# ET6801 register map
Vendor: ETMCU Inc.; File version: v0.0.1
CPU: CM7 r2p1, little endian, MPU, FPU, I-cache, D-cache, ITCM, DTCM, 4 interrupt priority bits
Registers are 32-bit, read-write, reset 0x0 unless marked. A register's access mark holds for its fields unless they carry their own. Offsets are from the block's base; [hi:lo] are bit positions; lines under a group give offsets from that group; {n}, {i} and the like mark numbered series.

## SRPWM0 — Provide an overview of the purpose and functionality of the peripheral: epwm_cfg
Base 0x40002000
Same registers: SRPWM{n} {0x40002000+0x1000*n} (n=1..17)
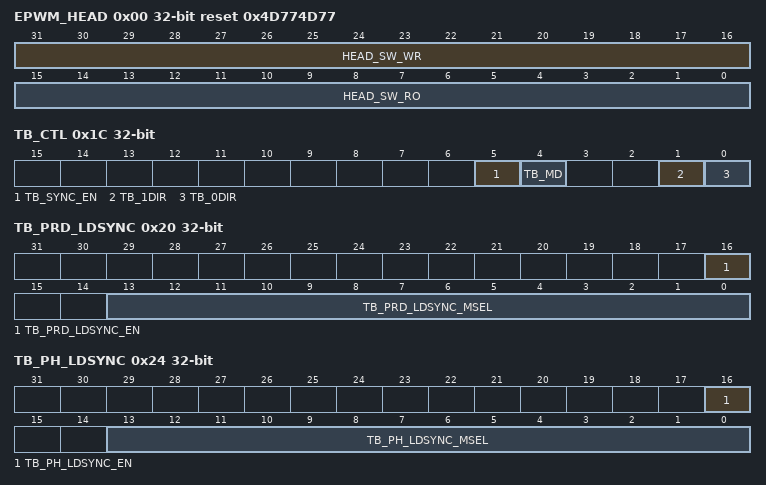
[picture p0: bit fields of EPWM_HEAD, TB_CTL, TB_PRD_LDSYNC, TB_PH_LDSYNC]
0x00 EPWM_HEAD reset 0x4D774D77
  [31:16] HEAD_SW_WR — 软件测试读写寄存器，硬件无访问
  [15:0] HEAD_SW_RO ro — 软件只读上报寄存器，硬件无访问,XXX的ASICII 码表示
0x10 TB_PRD
  [28:0] TB_PRD — timer_base计数周期配置。 高22bit为标准精度周期取值范围1~ 4194303（2^22-1），单位为SRPWM模块工作时钟周期； 低7bit为高精度周期，当高精度分辨率为156.25ps，低6比特对应0~(10-0.15625)ns，其中5ns~(10-0.15625)ns取值范围仅在上下计数模式下适用；当高精度辨率为78.125ps，低7比特对应0~(10-0.078125)ns，其中5ns~(10-0.078125)ns取值范围仅在上下计数模式下适用。 支持影子加载模式，在该模式下影子寄存器加载后才影响时基计数器的周期，影子加载同步信号选择参见CFG_TB_PRD_LDSYNC寄存器。
0x14 TB_0PHASE
  [21:0] TB_0PHASE — 时基同步信号0（从时基同步事件中选择）对应的相位配置，当时基同步信号0到来后计数器从该配置相位开始计数。支持影子加载，即配置的相位是影子加载寄存器生效后的值（影子加载寄存器生效需等相位同步加载信号生效）。
0x18 TB_1PHASE
  [21:0] TB_1PHASE — 时基同步信号1对应的相位配置，当时基同步信号1到来后计数器从该配置相位开始计数。注意！不支持影子加载，即直接使用cpu配置下来的值。
0x1C TB_CTL
  [5] TB_SYNC_EN — timer_base计数器使能（即epwm_cfg_en）是否等时基同步信号0（即sync_in0）到来后再开启使能。 注意！此配置项不止影响TIMER_BASE的计数功能，实际要影响当前通道cfg_epwm_en的生效！ 0：不用等时基同步信号，当前通道的epwm_cfg_en配置后立即生效； 1：需要等时基同步信号0预生效后，软件下发的当前通道epwm_cfg_en的值才生效，在epwm_cfg_en生效为1之前，除POSTPROTECT和SHADOW功能外的其余模块功能均不起作用。 时基同步事件包括 ，时基同步信号0的事件选择由cfg_tb_sync0_msel确定。另外，请注意前述描述中的预生效，是指事件满足立即生效，而后面描述中的时基同步信号0/1生效，是指时基同步事件满足后经过一个时钟周期的延迟后生效。
  [4] TB_MD — timer_base计数模式： 0：UP-DOWN计数； 1：UP计数。
  [1] TB_1DIR — 同步信号1计数方向，当时基同步信号1生效后计数器以该配置方向开始计数。 0：DOWN计数 1：UP计数。
  [0] TB_0DIR — 同步信号0计数方向，当时基同步信号0生效后计数器以该配置方向开始计数。 0：DOWN计数 1：UP计数。
0x20 TB_PRD_LDSYNC
  [16] TB_PRD_LDSYNC_EN — timer_base周期同步加载使能配置。 0：不同步加载，配置后立即生效； 1：同步加载，配置后等周期同步加载信号（来自于对同步加载事件集合1的选择）到来后生效。
  [13:0] TB_PRD_LDSYNC_MSEL — timer_base周期同步加载同步信号选择，从同步加载事件集合1中选择，采用Mask_OR的方式。
0x24 TB_PH_LDSYNC
  [16] TB_PH_LDSYNC_EN — timer_base相位同步加载使能配置。 0：不同步加载，配置后cfg_tb_0phase立即生效； 1：同步加载，配置后等相位同步加载信号（来自于对同步加载事件集合1的选择）到来后cfg_tb_0phase才生效。 注意： 这里的同步信号到来后生效是指同步信号到来后此配置值可用，并不是已加载到时基计数器中，真正加载到时基计数器中改变其相位，需等时基同步信号0生效； cfg_tb_1phase不受此配置影响，cfg_tb_1phase只支持立即生效模式；
  [13:0] TB_PH_LDSYNC_MSEL — timer_base相位同步加载同步信号选择，从同步加载事件集合1中选择，采用Mask_OR的方式。
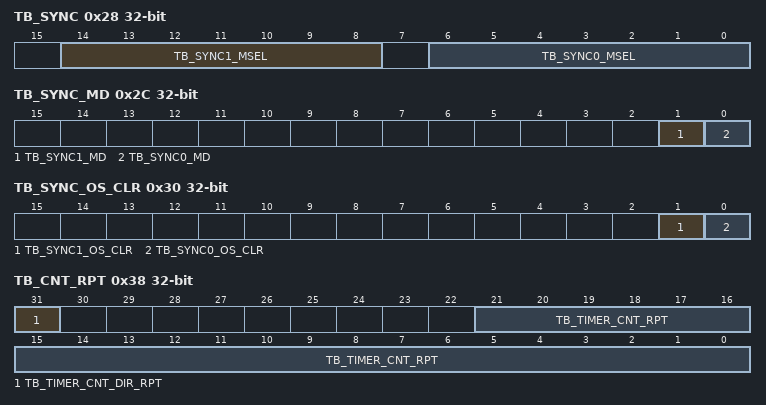
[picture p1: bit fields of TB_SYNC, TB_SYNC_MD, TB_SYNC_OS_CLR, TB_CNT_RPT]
0x28 TB_SYNC
  [14:8] TB_SYNC1_MSEL — timer_base 同步信号1选择，从时基计数器同步事件集合中选择，采用Mask_OR方式
  [6:0] TB_SYNC0_MSEL — timer_base 同步信号0选择，从时基计数器同步事件集合中选择，采用Mask_OR方式。
0x2C TB_SYNC_MD
  [1] TB_SYNC1_MD — timer_base 同步信号1的工作模式： 'b0：连续响应模式，只要有同步信号1出现，均会进行时基同步动作（将时基计数器计数值置为cfg_tb_1phase的活跃值）； 'b1：ONESHOT模式，出现一次同步信号1，并进行相应的时基同步动作后，不再响应后继的同步信号1，直至寄存器cfg_tb_sync1_os_clr写1产生清零脉冲再响应下一次同步信号1。
  [0] TB_SYNC0_MD — timer_base 同步信号0的工作模式： 'b0：连续响应模式，只要有同步信号0出现，均会进行时基同步动作（将时基计数器计数值置为cfg_tb_0phase的活跃值）； 'b1：ONESHOT模式，出现一次同步信号0，并进行相应的时基同步动作后，不再响应后继的同步信号0，直至寄存器cfg_tb_sync0_os_clr写1产生清零脉冲再响应下一次同步信号0。
0x30 TB_SYNC_OS_CLR
  [1] TB_SYNC1_OS_CLR — timer_base 同步信号1的ONESHOT锁存清除，写1产生脉冲。在ONESHOT工作模式下的同步信号1响应一次后忽略后继同步信号1，当前寄存器写1产生脉冲后，方可继续再响应下一次同步信号1。
  [0] TB_SYNC0_OS_CLR — timer_base 同步信号0的ONESHOT锁存清除，写1产生脉冲。在ONESHOT工作模式下的同步信号0响应一次后忽略后继同步信号0，当前寄存器写1产生脉冲后，方可继续再响应下一次同步信号0。
0x34 TB_RPT
  [0] TB_TIMER_OVER_RPT — timer_base 计数器溢出上报寄存器，当timer计数异常等于16'hFFFF时上报告警。软件写1清零。
0x38 TB_CNT_RPT ro
  [31] TB_TIMER_CNT_DIR_RPT — timer_base 计数器的计数方向实时上报
  [21:0] TB_TIMER_CNT_RPT — timer_base 计数器的计数值实时上报
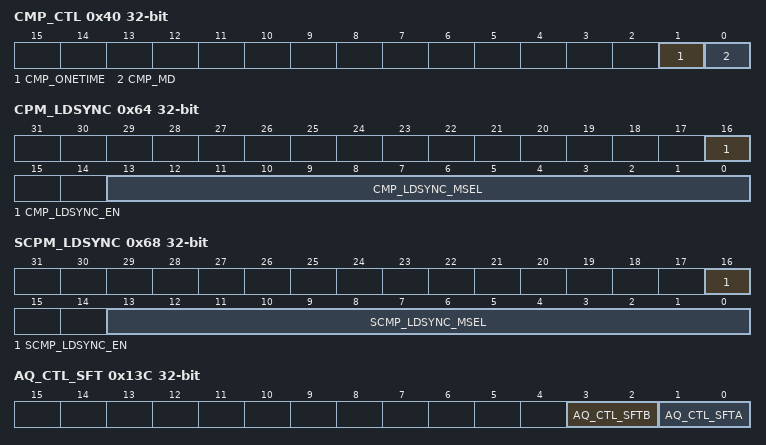
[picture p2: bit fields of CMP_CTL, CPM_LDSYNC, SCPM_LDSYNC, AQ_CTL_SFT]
0x40 CMP_CTL
  [1] CMP_ONETIME — 在一个UP或DOWN的方向上只产生1次比较事件或多次事件配置。 0：产生多次事件； 1：只产生1次事件。
  [0] CMP_MD — 0：主比较器向上或向下方向产生相等事件； 1：主比较器向上方向产生大于等于事件，向下方向产生小于等于事件。
0x44 CMP_CMPA
  [27:0] CMP_CMPA — 主比较事件A的比较位置配置。 高22bit为标准精度比较值，可用于产生比较事件，低6bit为高精度，用于高精度发波信号的占空比微调，当高精度分辨率为156.25ps，低5比特有效，对应0~(5-0.15625)ns；当高精度辨率为78.125ps，低6比特有效，对应0~(5-0.078125)ns。
0x48 CMP_CMPB
  [27:0] CMP_CMPB — 主比较事件B的比较位置配置。 高22bit为标准精度比较值，可用于产生比较事件，低6bit为高精度，用于高精度发波信号的占空比微调，当高精度分辨率为156.25ps，低5比特有效，对应0~(5-0.15625)ns；当高精度辨率为78.125ps，低6比特有效，对应0~(5-0.078125)ns。
0x4C CMP_CMPC
  [27:0] CMP_CMPC — 主比较事件C的比较位置配置。 高22bit为标准精度比较值，可用于产生比较事件，低6bit为高精度，用于高精度发波信号的占空比微调，当高精度分辨率为156.25ps，低5比特有效，对应0~(5-0.15625)ns；当高精度辨率为78.125ps，低6比特有效，对应0~(5-0.078125)ns。
0x50 CMP_CMPD
  [27:0] CMP_CMPD — 主比较事件D的比较位置配置。 高22bit为标准精度比较值，可用于产生比较事件，低6bit为高精度，用于高精度发波信号的占空比微调，当高精度分辨率为156.25ps，低5比特有效，对应0~(5-0.15625)ns；当高精度辨率为78.125ps，低6比特有效，对应0~(5-0.078125)ns。
0x54 CMP_SCMPA
  [21:0] CMP_SCMPA — 从比较事件A的比较位置配置。
0x58 CMP_SCMPB
  [21:0] CMP_SCMPB — 从比较事件B的比较位置配置。
0x5C CMP_SCMPC
  [21:0] CMP_SCMPC — 从比较事件C的比较位置配置。
0x60 CMP_SCMPD
  [21:0] CMP_SCMPD — 从比较事件D的比较位置配置。
0x64 CPM_LDSYNC
  [16] CMP_LDSYNC_EN — 主比较事件同步加载使能配置。 0：不同步加载，配置后立即生效； 1：同步加载，配置后等同步信号到来后生效。
  [13:0] CMP_LDSYNC_MSEL — 主比较事件同步加载同步信号选择，从同步加载事件集合1中选择，采用Mask_OR方式。
0x68 SCPM_LDSYNC
  [16] SCMP_LDSYNC_EN — 从比较事件同步加载使能配置。 0：不同步加载，配置后立即生效； 1：同步加载，配置后等同步信号到来后生效。
  [13:0] SCMP_LDSYNC_MSEL — 从比较事件同步加载同步信号选择，从同步加载事件集合1中选择，采用Mask_OR方式。
{0x80+4i} AQ_CTLA[{i}] (i=0..21) — AQ_CTLA%S
  [1:0] AQ_CTLA — 产生epwma信号的动作矩阵配置，对于每一个可能触发AQ动作的事件均有一个地址对应其动作配置。共有22个动作矩阵事件可用来触发动作矩阵动作，参见《ET6001 SPWM模块逻辑需求规格书》中关于动作矩阵事件集合的定义。 00：不动作； 01：输出ePWMA和/或ePWMB 置0； 10：输出ePWMA和/或ePWMB 置1； 11：输出ePWMA和/或ePWMB 取反；
{0xE0+4i} AQ_CTLB[{i}] (i=0..21) — AQ_CTLB%S
  [1:0] AQ_CTLB — 产生epwmb信号的动作矩阵配置。对于每一个可能触发AQ动作的事件均有一个地址对应其动作配置。共有22个动作矩阵事件可用来触发动作矩阵动作，参见《ET6002 SRPWM模块逻辑需求规格书》中关于动作矩阵事件集合的定义。 00：不动作； 01：输出ePWMA和/或ePWMB 置0； 10：输出ePWMA和/或ePWMB 置1； 11：输出ePWMA和/或ePWMB 取反；
0x13C AQ_CTL_SFT
  [3:2] AQ_CTL_SFTB — 软件产生epwmb信号的动作矩阵配置。配1产生软件强制动作，优先级高于其他22个动作矩阵事件。
  [1:0] AQ_CTL_SFTA — 软件产生epwma信号的动作矩阵配置。配1产生软件强制动作，优先级高于其他22个动作矩阵事件。
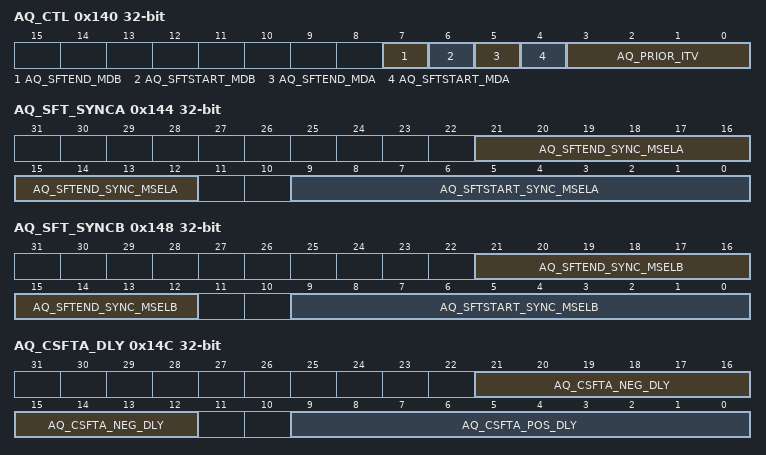
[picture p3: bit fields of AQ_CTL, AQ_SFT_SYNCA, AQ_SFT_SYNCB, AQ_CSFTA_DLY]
0x140 AQ_CTL
  [7] AQ_SFTEND_MDB — epwmb信号软件强制动作结束模式配置 0：不同步；cfg_aq_ctl_sftb写0后，软件强制动作立即失效。 1：同步；cfg_aq_ctl_sftb写0后，还需等待结束同步信号生效，软件强制动作才失效。
  [6] AQ_SFTSTART_MDB — epwmb信号软件强制动作起始模式配置 0：不同步；cfg_aq_ctl_sftb写1后，软件强制动作立即生效。 1：同步；cfg_aq_ctl_sftb写1后，还需等待开始同步信号生效，软件强制动作才生效。
  [5] AQ_SFTEND_MDA — epwma信号软件强制动作结束模式配置 0：不同步；cfg_aq_ctl_sfta写0后，软件强制动作立即失效。 1：同步；cfg_aq_ctl_sfta写0后，还需等待结束同步信号生效，软件强制动作才失效。
  [4] AQ_SFTSTART_MDA — epwma信号软件强制动作起始模式配置 0：不同步；cfg_aq_ctl_sfta写1后，软件强制动作立即生效。 1：同步；cfg_aq_ctl_sfta写1后，还需等待开始同步信号生效，软件强制动作才生效。
  [3:0] AQ_PRIOR_ITV — 动作矩阵优先级间隔长度配置。
0x144 AQ_SFT_SYNCA
  [21:12] AQ_SFTEND_SYNC_MSELA — epwma信号软件强制动作结束同步信号选择。从AQ同步事件集合中选择。采用Mask_OR方式
  [9:0] AQ_SFTSTART_SYNC_MSELA — epwma信号软件强制动作起始同步信号选择。从AQ同步事件集合中选择。采用Mask_OR方式
0x148 AQ_SFT_SYNCB
  [21:12] AQ_SFTEND_SYNC_MSELB — epwmb信号软件强制动作结束同步信号选择。从AQ同步事件集合中选择。采用Mask_OR方式
  [9:0] AQ_SFTSTART_SYNC_MSELB — epwmb信号软件强制动作起始同步信号选择。从AQ同步事件集合中选择。采用Mask_OR方式
0x14C AQ_CSFTA_DLY
  [21:12] AQ_CSFTA_NEG_DLY — epwma信号软件触发持续动作的下降沿后推延迟配置。
  [9:0] AQ_CSFTA_POS_DLY — epwma信号软件触发持续动作的上升沿后推延迟配置。
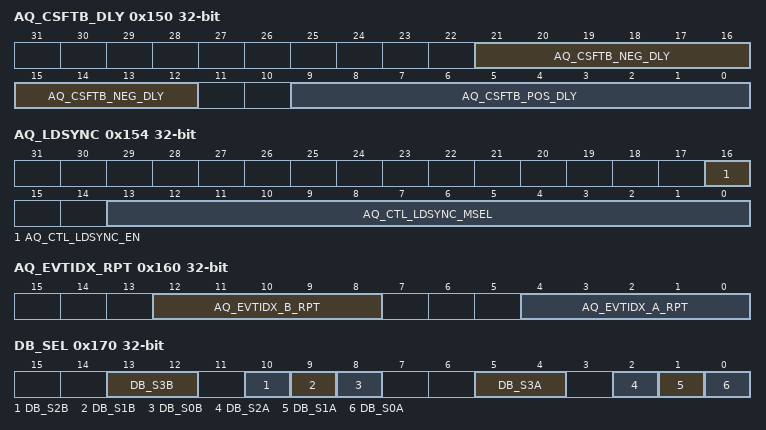
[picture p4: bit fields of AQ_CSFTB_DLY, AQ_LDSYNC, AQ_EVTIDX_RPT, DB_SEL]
0x150 AQ_CSFTB_DLY
  [21:12] AQ_CSFTB_NEG_DLY — epwmb信号软件触发持续动作的下降沿后推延迟配置。
  [9:0] AQ_CSFTB_POS_DLY — epwmb信号软件触发持续动作的上升沿后推延迟配置。
0x154 AQ_LDSYNC
  [16] AQ_CTL_LDSYNC_EN — AQ动作矩阵同步加载使能配置。 0：不同步加载，配置后立即生效； 1：同步加载，配置后等同步信号到来后生效。
  [13:0] AQ_CTL_LDSYNC_MSEL — AQ动作矩阵同步加载同步信号选择，从同步加载事件集合2中选择，采用Mask_OR方式
0x160 AQ_EVTIDX_RPT ro
  [12:8] AQ_EVTIDX_B_RPT — 产生动作矩阵B的事件优先级排序后的索引；具体索引对应事件： ；用于维测。
  [4:0] AQ_EVTIDX_A_RPT — 产生动作矩阵A的事件优先级排序后的索引；具体索引对应事件： ；用于维测。
0x170 DB_SEL
  [13:12] DB_S3B — epwmb信号死区第3个MUX选择 0：选择不做任何延迟的，旁路输出，即选择DB模块的输入作为输出； 1：选择经过上升沿或下降沿延迟之后的，即第2个MUX的输出。 2：选择将第2个MUX的输出取反后输出。
  [10] DB_S2B — epwmb信号死区第2个MUX选择 0：选择不做下降沿延迟的，即选择第1个MUX的输入作为输出； 1：选择下降沿延迟之后的。
  [9] DB_S1B — epwmb信号死区第1个MUX，选择送往下降沿延迟逻辑的信号 0：选择不做上升沿延迟，即选择第0个MUX的输入作为输出； 1：选择上升沿延迟之后的。
  [8] DB_S0B — epwmb信号死区第0个MUX，选择送往上升沿延迟逻辑的信号。 0：选择epwmb信号； 1：选择epwma信号。
  [5:4] DB_S3A — epwma信号死区第3个MUX选择 0：选择不做任何延迟的，旁路输出，即选择DB模块的输入作为输出； 1：选择经过上升沿或下降沿延迟之后的，即第2个MUX的输出。 2：选择将第2个MUX的输出取反后输出。
  [2] DB_S2A — epwma信号死区第2个MUX选择 0：选择不做下降沿延迟的，即选择第1个MUX的输入作为输出； 1：选择下降沿延迟之后的。
  [1] DB_S1A — epwma信号死区第1个MUX选择，选择送往下降沿延迟逻辑的信号 0：选择不做上升沿延迟，即选择第0个MUX的输入作为输出； 1：选择上升沿延迟之后的。
  [0] DB_S0A — epwma信号死区第0个MUX选择 0：选择epwma信号； 1：选择epwmb信号。
0x174 DB_APOS_DLY
  [19:0] DB_APOS_DLY — epwma 上升沿延迟配置。高14bit为低精度，用于DB模块调整发波信号上升沿，低6bit为高精度，用于微调高精度发波信号的上升沿。
0x178 DB_ANEG_DLY
  [19:0] DB_ANEG_DLY — epwma 下降沿延迟配置。高14bit为低精度，用于DB模块调整发波信号下降沿，低6bit为高精度，用于微调高精度发波信号的下降沿。
0x17C DB_BPOS_DLY
  [19:0] DB_BPOS_DLY — epwmb 上升沿延迟配置。高14bit为低精度，用于DB模块调整发波信号上升沿，低6bit为高精度，用于微调高精度发波信号的上升沿。
0x180 DB_BNEG_DLY
  [19:0] DB_BNEG_DLY — epwmb 下降沿延迟配置。高14bit为低精度，用于DB模块调整发波信号下降沿，低6bit为高精度，用于微调高精度发波信号的下降沿。
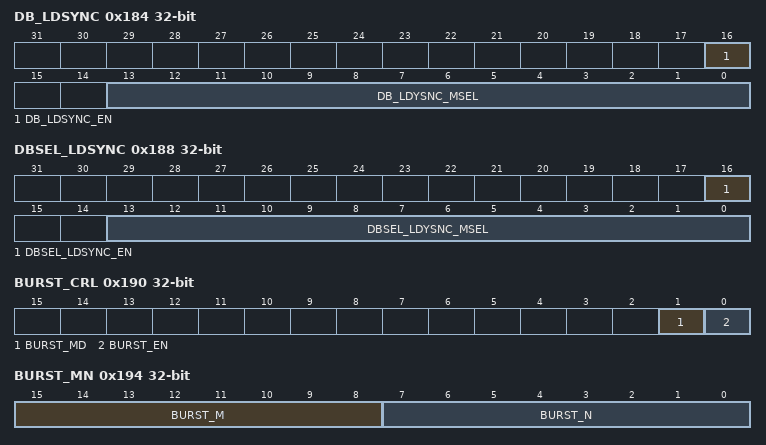
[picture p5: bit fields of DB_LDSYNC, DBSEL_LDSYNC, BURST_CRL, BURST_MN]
0x184 DB_LDSYNC
  [16] DB_LDSYNC_EN — 死区配置同步加载使能配置。 0：不同步加载，配置后立即生效； 1：同步加载，配置后等同步信号到来后生效。
  [13:0] DB_LDYSNC_MSEL — 死区同步加载同步信号选择，从同步加载事件集合2中选择，采用Mask_OR的方式。
0x188 DBSEL_LDSYNC
  [16] DBSEL_LDSYNC_EN — CFG_DB_SEL寄存器的同步加载使能。 0：不同步加载，配置后立即生效； 1：同步加载，配置后等同步信号到来后生效。
  [13:0] DBSEL_LDYSNC_MSEL — CFG_DB_SEL寄存器的同步加载同步信号选择，从同步加载事件集合2中选择，采用Mask_OR的方式。
0x190 BURST_CRL
  [1] BURST_MD — Burst模式选择配置。 0：Burst模式时先不发波； 1：Burst模式时先发波。
  [0] BURST_EN — Burst模块使能配置。 0：不使能； 1：使能。
0x194 BURST_MN
  [15:8] BURST_M — Burst模式M个周期配置。BURST模式使能后，在M个周期中有N个周期发波，M-N个周期不发波。
  [7:0] BURST_N — Burst模式n个周期发波配置。
0x198 BURST_SYNC_SEL
  [5:0] BURST_SYNC_MSEL — 开始发Burst波的同步信号选择，从BURST同步事件集合中选择，采用Mask_OR的方式。
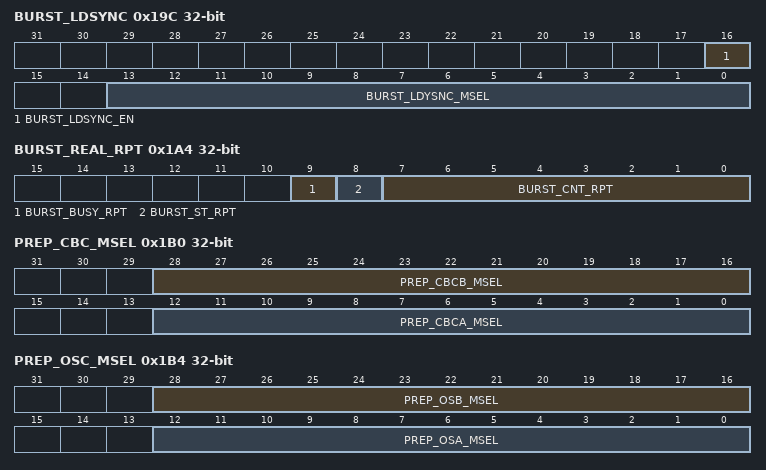
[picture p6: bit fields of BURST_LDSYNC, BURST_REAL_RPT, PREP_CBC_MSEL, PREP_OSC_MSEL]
0x19C BURST_LDSYNC
  [16] BURST_LDSYNC_EN — Burst模式m和n配置同步加载使能配置。 0：不同步加载，配置后立即生效； 1：同步加载，配置后等同步信号到来后生效。
  [13:0] BURST_LDYSNC_MSEL — Burst模式m和n配置同步信号选择，从同步加载事件集合1选择，采用Mask_OR的方式。
0x1A4 BURST_REAL_RPT ro
  [9] BURST_BUSY_RPT — BURST busy状态上报，为1表示当前还工作在BURST状态中；为0表示退出了BURST工作状态。
  [8] BURST_ST_RPT — BURST 状态上报；0: 表示BUSRT处于M/N的N个发波区间； 1: 表示BUSRT处于m/n 的M-N个不发波区间。
  [7:0] BURST_CNT_RPT — BURST 1~n次计数器的计数上报；用于维测
0x1B0 PREP_CBC_MSEL
  [28:16] PREP_CBCB_MSEL — 对epwmb信号进行CBC异常保护的mask_or选择信号，对于同步保护动作，从以下事件选择：
  [12:0] PREP_CBCA_MSEL — 对epwma信号进行CBC异常保护的mask_or选择信号，对于同步保护动作，从以下事件选择：
0x1B4 PREP_OSC_MSEL
  [28:16] PREP_OSB_MSEL — 对epwmb信号进行one shot异常保护的mask_or选择信号，对于同步保护动作，从以下事件选择：
  [12:0] PREP_OSA_MSEL — 对epwma信号进行one shot异常保护的mask_or选择信号，对于同步保护动作，从以下事件选择：
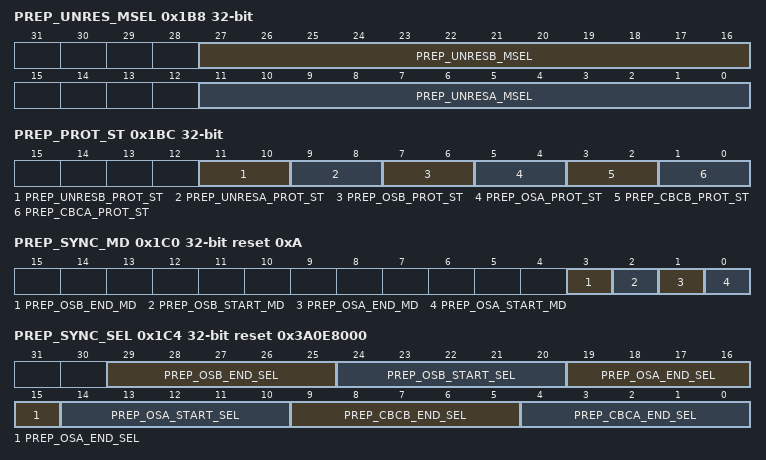
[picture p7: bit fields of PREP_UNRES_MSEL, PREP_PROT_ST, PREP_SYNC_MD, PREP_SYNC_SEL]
0x1B8 PREP_UNRES_MSEL
  [27:16] PREP_UNRESB_MSEL — 对epwma信号进行无约束异常保护的mask选择信号，对于同步保护动作，从以下事件选择：
  [11:0] PREP_UNRESA_MSEL — 对epwmb信号进行无约束异常保护的mask选择信号，对于同步保护动作，从以下事件选择：
0x1BC PREP_PROT_ST
  [11:10] PREP_UNRESB_PROT_ST — 对epwmb信号进行自由保护时保护状态配置。 00：高阻； 01：输出0； 10：输出1； 11：取反。
  [9:8] PREP_UNRESA_PROT_ST — 对epwma信号进行自由保护时保护状态配置。 00：高阻； 01：输出0； 10：输出1； 11：取反。
  [7:6] PREP_OSB_PROT_ST — 对epwmb信号进行one shot保护时保护状态配置。 00：高阻； 01：输出0； 10：输出1； 11：取反。
  [5:4] PREP_OSA_PROT_ST — 对epwma信号进行one shot保护时保护状态配置。 00：高阻； 01：输出0； 10：输出1； 11：取反。
  [3:2] PREP_CBCB_PROT_ST — 对epwmb信号进行CBC保护时保护状态配置。 00：高阻； 01：输出0； 10：输出1； 11：取反。
  [1:0] PREP_CBCA_PROT_ST — 对epwma信号进行CBC保护时保护状态配置。 00：高阻； 01：输出0； 10：输出1； 11：取反。
0x1C0 PREP_SYNC_MD reset 0xA
  [3] PREP_OSB_END_MD — 对epwmb信号进行one shot保护时是否需要同步结束配置，默认需要同步结束。 0：不需要同步； 1：需要同步。
  [2] PREP_OSB_START_MD — 对epwmb信号进行one shot保护时是否需要同步开始配置。 0：不需要同步； 1：需要同步。
  [1] PREP_OSA_END_MD — 对epwma信号进行one shot保护时是否需要同步结束配置，默认需要同步结束。 0：不需要同步； 1：需要同步。
  [0] PREP_OSA_START_MD — 对epwma信号进行one shot保护时是否需要同步开始配置。 0：不需要同步； 1：需要同步。
0x1C4 PREP_SYNC_SEL reset 0x3A0E8000
  [29:25] PREP_OSB_END_SEL — epwmb信号oneshot保护结束同步信号选择，从所有事件集合中选择，默认以软件强制事件结束。
  [24:20] PREP_OSB_START_SEL — epwmb信号oneshot保护起始同步信号选择，从所有事件集合中选择。
  [19:15] PREP_OSA_END_SEL — epwma信号oneshot保护结束同步信号选择，从所有事件集合中选择，默认以软件强制事件结束。
  [14:10] PREP_OSA_START_SEL — epwma信号oneshot保护起始同步信号选择，从所有事件集合中选择。
  [9:5] PREP_CBCB_END_SEL — epwmb信号CBC保护结束同步信号选择，从所有事件集合中选择。
  [4:0] PREP_CBCA_END_SEL — epwma信号CBC保护结束同步信号选择，从所有事件集合中选择。
0x1C8 PREP_UNRES_MIN_TIME
  [15:0] PREP_UNRES_MIN_TIME — 无约束保护最小脉宽时间配置。单位为PWM模块工作时钟周期数。
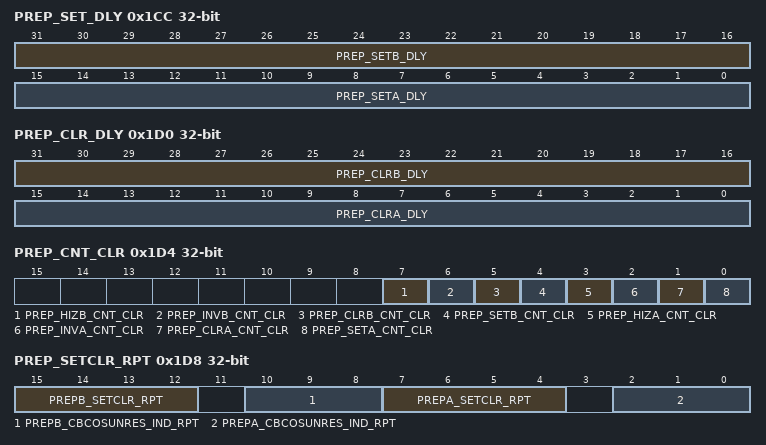
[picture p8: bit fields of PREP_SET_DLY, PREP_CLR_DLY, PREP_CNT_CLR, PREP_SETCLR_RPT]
0x1CC PREP_SET_DLY
  [31:16] PREP_SETB_DLY — epwmb置1保护动作延迟配置，取值范围0~65535，单位为SPWM模块工作时钟周期。该配置值将相应保护动作实际起始时间延后（保护动作结束时间不受影响），当置'd0值时，保护动作不做延迟，配置值为N时，保护动作起始时间延后N个时钟周期。保护动作结束时刻不受此配置值影响。 准静态配置寄存器，在pwm_en为低时才能改变配置
  [15:0] PREP_SETA_DLY — epwma置1保护动作延迟配置，取值范围0~65535，单位为SPWM模块工作时钟周期。该配置值将相应保护动作实际起始时间延后（保护动作结束时间不受影响），当置'd0值时，保护动作不做延迟，配置值为N时，保护动作起始时间延后N个时钟周期。保护动作结束时刻不受此配置值影响。 准静态配置寄存器，在pwm_en为低时才能改变配置。
0x1D0 PREP_CLR_DLY
  [31:16] PREP_CLRB_DLY — epwmb清零保护动作延迟配置，取值范围0~65535，单位为SPWM模块工作时钟周期。该配置值将相应保护动作实际起始时间延后（保护动作结束时间不受影响），当置'd0值时，保护动作不做延迟，配置值为N时，保护动作起始时间延后N个时钟周期。保护动作结束时刻不受此配置值影响。 准静态配置寄存器，在pwm_en为低时才能改变配置
  [15:0] PREP_CLRA_DLY — epwma清零保护动作延迟配置，取值范围0~65535，单位为SPWM模块工作时钟周期。该配置值将相应保护动作实际起始时间延后（保护动作结束时间不受影响），当置'd0值时，保护动作不做延迟，配置值为N时，保护动作起始时间延后N个时钟周期。保护动作结束时刻不受此配置值影响。 准静态配置寄存器，在pwm_en为低时才能改变配置。
0x1D4 PREP_CNT_CLR
  [7] PREP_HIZB_CNT_CLR — epwmb 高阻时间计数器清零，写1清零；
  [6] PREP_INVB_CNT_CLR — epwmb 取反时间计数器清零，写1清零；
  [5] PREP_CLRB_CNT_CLR — epwmb 清零时间计数器清零，写1清零；
  [4] PREP_SETB_CNT_CLR — epwmb 置1时间计数器清零，写1清零；
  [3] PREP_HIZA_CNT_CLR — epwma 高阻时间计数器清零，写1清零；
  [2] PREP_INVA_CNT_CLR — epwma 取反时间计数器清零，写1清零；
  [1] PREP_CLRA_CNT_CLR — epwma 清零时间计数器清零，写1清零；
  [0] PREP_SETA_CNT_CLR — epwma 置1时间计数器清零，写1清零；
0x1D8 PREP_SETCLR_RPT ro
  [15:12] PREPB_SETCLR_RPT — 控制epwmb信号置1，清零，取反和输出高阻的指示信号上报。 bit0：输出高阻指示； bit1：输出取反指示； bit2：输出清零指示； bit3：输出置1指示。
  [10:8] PREPB_CBCOSUNRES_IND_RPT — 控制epwmb信号oneshot指示，cbc指示以及无约束保护指示上报 bit0：无约束保护指示；bit1：oneshot保护指示；bit2：CBC保护指示。
  [7:4] PREPA_SETCLR_RPT — 控制epwma信号置1，清零，取反和输出高阻的指示信号上报。 bit0：输出高阻指示； bit1：输出取反指示； bit2：输出清零指示； bit3：输出置1指示。
  [2:0] PREPA_CBCOSUNRES_IND_RPT — 控制epwma信号oneshot指示，cbc指示以及自由保护指示上报 bit0：无约束保护指示；bit1：oneshot保护指示；bit2：CBC保护指示。
0x1DC PREPA_SET_CNT_RPT ro
  [21:0] PREPA_SET_CNT_RPT — epwma被异常置1的时间长度计数上报。
0x1E0 PREPB_SET_CNT_RPT ro
  [21:0] PREPB_SET_CNT_RPT — epwmb被异常置1的时间长度计数上报。
0x1E4 PREPA_CLR_CNT_RPT ro
  [21:0] PREPA_CLR_CNT_RPT — epwma被异常清零的时间长度计数上报。
0x1E8 PREPB_CLR_CNT_RPT ro
  [21:0] PREPB_CLR_CNT_RPT — epwmb被异常清零的时间长度计数上报。
0x1EC PREPA_INV_CNT_RPT ro
  [21:0] PREPA_INV_CNT_RPT — epwma被异常取反的时间长度计数上报。
0x1F0 PREPB_INV_CNT_RPT ro
  [21:0] PREPB_INV_CNT_RPT — epwmb被异常取反的时间长度计数上报。
0x1F4 PREPA_HIZ_CNT_RPT ro
  [21:0] PREPA_HIZ_CNT_RPT — epwma被异常置高阻的时间长度计数上报。
0x1F8 PREPB_HIZ_CNT_RPT ro
  [21:0] PREPB_HIZ_CNT_RPT — epwmb被异常置高阻的时间长度计数上报。
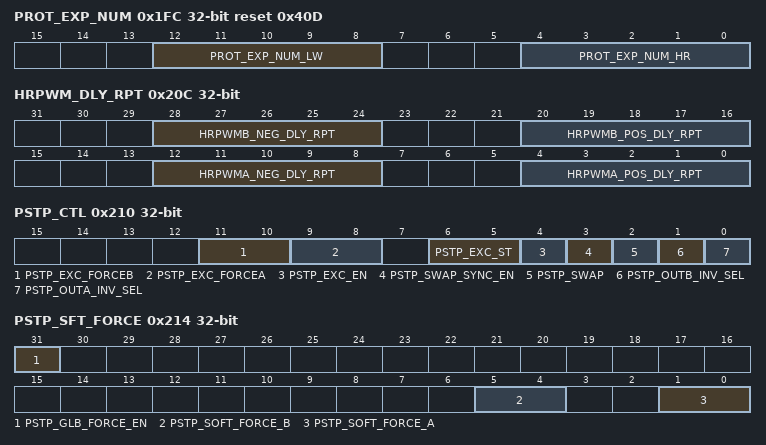
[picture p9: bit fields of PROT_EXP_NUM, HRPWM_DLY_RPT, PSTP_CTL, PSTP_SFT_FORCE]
0x1FC PROT_EXP_NUM reset 0x40D
  [12:8] PROT_EXP_NUM_LW — 未启用高精度时，快速保护动作脉冲扩展时钟周期，当扩展前脉冲宽度小于cfg_prot_exp_num_lw+1，则扩展后脉冲宽度变为cfg_prot_exp_num_lw+1，如果扩展前脉冲宽度大于等于cfg_prot_exp_num_lw+1，则扩展后脉冲宽度不变： 'd0：不做脉冲扩展； 'd1：扩展一个时钟周期； ... 准静态配置寄存器，在pwm_en为低时才能改变配置
  [4:0] PROT_EXP_NUM_HR — 高精度生效时，快速保护动作脉冲扩展时钟周期，当扩展前脉冲宽度小于cfg_prot_exp_num_hr +1，则扩展后脉冲宽度变为cfg_prot_exp_num_hr +1，如果扩展前脉冲宽度大于等于cfg_prot_exp_num_hr +1，则扩展后脉冲宽度不变： 'd0：不做脉冲扩展； 'd1：扩展一个时钟周期； ... 准静态配置寄存器，在pwm_en为低时才能改变配置。
0x200 HRPWM_BPS
  [1] HRPWM_BPS — 高精度PWM旁路使能。 0：不旁路； 1：旁路。
0x20C HRPWM_DLY_RPT ro
  [28:24] HRPWMB_NEG_DLY_RPT — ePWMB的下降沿的高精度延迟值上报。
  [20:16] HRPWMB_POS_DLY_RPT — ePWMB的上升沿的高精度延迟值上报。
  [12:8] HRPWMA_NEG_DLY_RPT — ePWMA的下降沿的高精度延迟值上报。
  [4:0] HRPWMA_POS_DLY_RPT — ePWMA的上升沿的高精度延迟值上报。
0x210 PSTP_CTL
  [11:10] PSTP_EXC_FORCEB — epwma和epwmb互斥后b输出状态配置。 00：不动作； 01：输出1； 10：输出0； 11：输出高阻。
  [9:8] PSTP_EXC_FORCEA — epwma和epwmb互斥后a输出状态配置。 00：不动作； 01：输出1； 10：输出0； 11：输出高阻。
  [6:5] PSTP_EXC_ST — epwma和epwmb互斥状态配置。 00：a和b同时为低产生互斥； 01：a为低，b为高产生互斥； 10：a为高，b为低产生互斥； 11：a和b同时为高产生互斥。
  [4] PSTP_EXC_EN — epwm输出互斥检测使能 0：不使能； 1：使能。
  [3] PSTP_SWAP_SYNC_EN — epwma和epwmb输出交换是否需要等到同步信号再交换选择。 0：不需要同步； 1：需要同步。
  [2] PSTP_SWAP — epwma和epwmb输出信号是否需要交换选择； 0：不交换； 1：交换。
  [1] PSTP_OUTB_INV_SEL — epwmb输出是否取反选择 0：不取反 1：取反
  [0] PSTP_OUTA_INV_SEL — epwma输出是否取反选择 0：不取反 1：取反
0x214 PSTP_SFT_FORCE
  [31] PSTP_GLB_FORCE_EN — 多通道同步强制输出状态使能； 0：强制输出状态配置后立即生效，与其他通道不相关； 1：强制输出状态配置后，需等待公共寄存器CFG_PSTP_MULTI_SFT_EVT/ CFG_PSTP_MCHAN_FORCE_TRG下发当前通道对应的触发脉冲才生效。
  [5:4] PSTP_SOFT_FORCE_B — b支路软件强制输出状态配置。 00：不动作； 01：强制输出1； 10：强制输出0； 11：强制输出高阻。
  [1:0] PSTP_SOFT_FORCE_A — a支路软件强制输出状态配置。 00：不动作； 01：强制输出1； 10：强制输出0； 11：强制输出高阻。
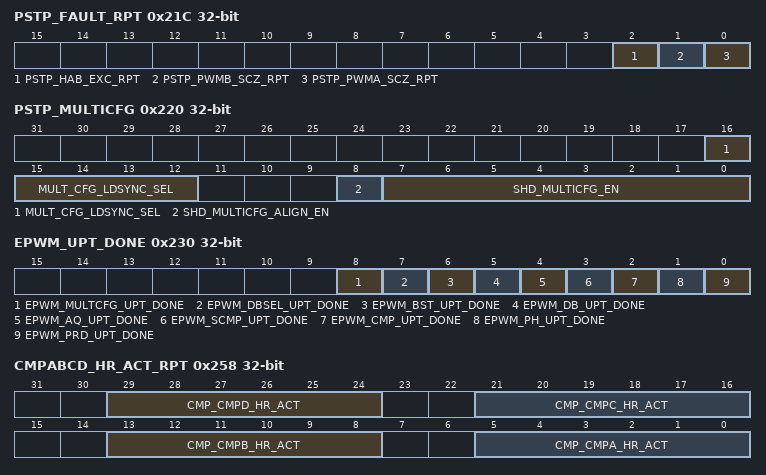
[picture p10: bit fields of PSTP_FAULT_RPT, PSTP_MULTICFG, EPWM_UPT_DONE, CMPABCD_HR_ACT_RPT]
0x21C PSTP_FAULT_RPT ro
  [2] PSTP_HAB_EXC_RPT — 后级保护模块高精度PWMA和PWMB产生互斥指示信号上报。
  [1] PSTP_PWMB_SCZ_RPT — 后级保护模块PWMB的异常置1（set），清零（clr），高阻（hiz）指示上报；
  [0] PSTP_PWMA_SCZ_RPT — 后级保护模块PWMA的异常置1（set），清零（clr），高阻（hiz）指示上报；
0x220 PSTP_MULTICFG
  [16:12] MULT_CFG_LDSYNC_SEL — 当使能多个寄存器同步更新时，选择统一的同步加载触发信号: 'd0：zero_evt 'd1：prd_evt 'd2：zero_evt或prd_evt 'd3：向上计数方向从比较事件A .... 'd6：向上计数方向从比较事件D 'd7：向下计数方向从比较事件A ... 'd10：向下计数方向从比较事件D 'd11：fpp_fault_pos[0] ... 'd14：fpp_fault_pos[4] 'd15：sync_in[0] 'd16：sync_in[1] d'17：burst_over 'd18：sft_evt
  [8] SHD_MULTICFG_ALIGN_EN — 支持多个配置寄存器是否需要同步到周期开始再更新使能。 0：不使能； 1：使能。 注意！当公共模块寄存器cfg_hw_conflt_adapt_mask的配置值为0,cfg_shd_multicfg_align_en的值必须配置为0。
  [7:0] SHD_MULTICFG_EN — 支持多个配置寄存器是否需要同步更新使能。 bit[7:0] 分别对应： 的更新
0x230 EPWM_UPT_DONE
  [8] EPWM_MULTCFG_UPT_DONE — 影子寄存器多个配置同步更新完成指示上报； 0：表示未更新完成； 1：表示更新完成。 软件写1清零。
  [7] EPWM_DBSEL_UPT_DONE — DBSEL影子寄存器同步更新结束指示上报，软件写1清零。 0：表示未更新完成； 1：表示更新完成。
  [6] EPWM_BST_UPT_DONE — BURST影子寄存器同步更新结束指示上报，软件写1清零。 0：表示未更新完成； 1：表示更新完成。
  [5] EPWM_DB_UPT_DONE — DB影子寄存器同步更新结束指示上报，软件写1清零。 0：表示未更新完成； 1：表示更新完成。
  [4] EPWM_AQ_UPT_DONE — AQ影子寄存器同步更新结束指示上报，软件写1清零。 0：表示未更新完成； 1：表示更新完成。
  [3] EPWM_SCMP_UPT_DONE — SCMP影子寄存器同步更新结束指示上报，软件写1清零。 0：表示未更新完成； 1：表示更新完成。
  [2] EPWM_CMP_UPT_DONE — CMP影子寄存器同步更新结束指示上报，软件写1清零。 0：表示未更新完成； 1：表示更新完成。
  [1] EPWM_PH_UPT_DONE — PHASE影子寄存器同步更新结束指示上报，软件写1清零。 0：表示未更新完成； 1：表示更新完成。
  [0] EPWM_PRD_UPT_DONE — PRD影子寄存器同步更新结束指示上报，软件写1清零。 0：表示未更新完成； 1：表示更新完成。
0x240 TB_PRD_ACT_RPT ro
  [28:0] TB_PRD_ACT — 正在使用的TB_PRD29位上报
0x244 TB_PHASE_ACT_RPT ro
  [21:0] TB_PHASE_ACT — 正在使用的PHASE上报
0x248 CMPA_ACT_RPT ro
  [21:0] CMP_CMPA_ACT — 正在使用的主比较事件A上报
0x24C CMPB_ACT_RPT ro
  [21:0] CMP_CMPB_ACT — 正在使用的主比较事件B上报
0x250 CMPC_ACT_RPT ro
  [21:0] CMP_CMPC_ACT — 正在使用的主比较事件C上报
0x254 CMPD_ACT_RPT ro
  [21:0] CMP_CMPD_ACT — 正在使用的主比较事件D上报
0x258 CMPABCD_HR_ACT_RPT ro
  [29:24] CMP_CMPD_HR_ACT — 正在使用的主比较事件D高精度部分上报
  [21:16] CMP_CMPC_HR_ACT — 正在使用的主比较事件C高精度部分上报
  [13:8] CMP_CMPB_HR_ACT — 正在使用的主比较事件B高精度部分上报
  [5:0] CMP_CMPA_HR_ACT — 正在使用的主比较事件A高精度部分上报
0x25C SCMPA_ACT_RPT ro
  [21:0] CMP_SCMPA_ACT — 正在使用的从比较事件A上报
0x260 SCMPB_ACT_RPT ro
  [21:0] CMP_SCMPB_ACT — 正在使用的从比较事件B上报
0x264 SCMPC_ACT_RPT ro
  [21:0] CMP_SCMPC_ACT — 正在使用的从比较事件C上报
0x268 SCMPD_ACT_RPT ro
  [21:0] CMP_SCMPD_ACT — 正在使用的从比较事件D上报
0x26C AQ_CTLA_ACT_L_RPT ro
  [31:0] AQ_CTLA_ACT_L — 正在使用的动作矩阵配置A低32bit上报
0x270 AQ_CTLA_ACT_H_RPT ro
  [11:0] AQ_CTLA_ACT_H — 正在使用的动作矩阵配置A 高12bit上报
0x274 AQ_CTLB_ACT_L_RPT ro
  [31:0] AQ_CTLB_ACT_L — 正在使用的动作矩阵配置B低32bit上报
0x278 AQ_CTLB_ACT_H_RPT ro
  [11:0] AQ_CTLB_ACT_H — 正在使用的动作矩阵配置B高12bit上报
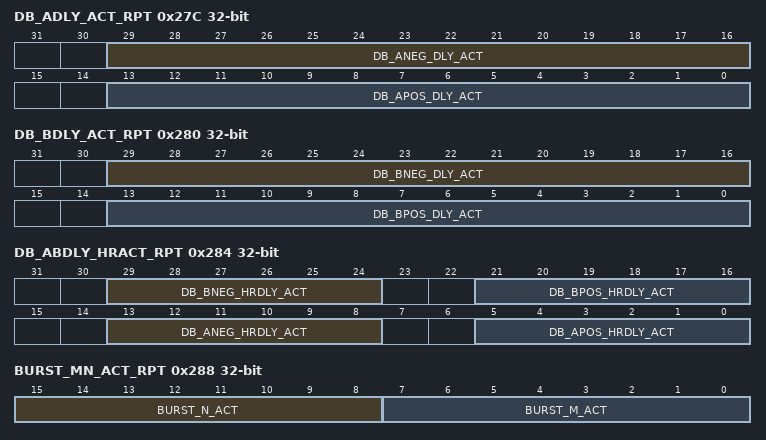
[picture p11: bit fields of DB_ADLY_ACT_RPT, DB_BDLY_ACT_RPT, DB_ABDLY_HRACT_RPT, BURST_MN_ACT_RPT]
0x27C DB_ADLY_ACT_RPT ro
  [29:16] DB_ANEG_DLY_ACT — ePWMA正在使用的死区下降沿延迟上报。
  [13:0] DB_APOS_DLY_ACT — ePWMA正在使用的死区上升沿延迟上报。
0x280 DB_BDLY_ACT_RPT ro
  [29:16] DB_BNEG_DLY_ACT — ePWMB正在使用的死区下降沿延迟上报。
  [13:0] DB_BPOS_DLY_ACT — ePWMB正在使用的死区上升沿延迟上报。
0x284 DB_ABDLY_HRACT_RPT ro
  [29:24] DB_BNEG_HRDLY_ACT — ePWMB正在使用的死区下降沿高精度延迟上报。
  [21:16] DB_BPOS_HRDLY_ACT — ePWMB正在使用的死区上升沿高精度延迟上报。
  [13:8] DB_ANEG_HRDLY_ACT — ePWMA正在使用的死区下降沿高精度延迟上报。
  [5:0] DB_APOS_HRDLY_ACT — ePWMA正在使用的死区上升沿高精度延迟上报。
0x288 BURST_MN_ACT_RPT ro
  [15:8] BURST_N_ACT — BURST正在使用的N值上报。
  [7:0] BURST_M_ACT — BURST正在使用的M值上报。
{0x300+0x20*i} FPP[{i}] (i=0..5) group — CFG_FPP
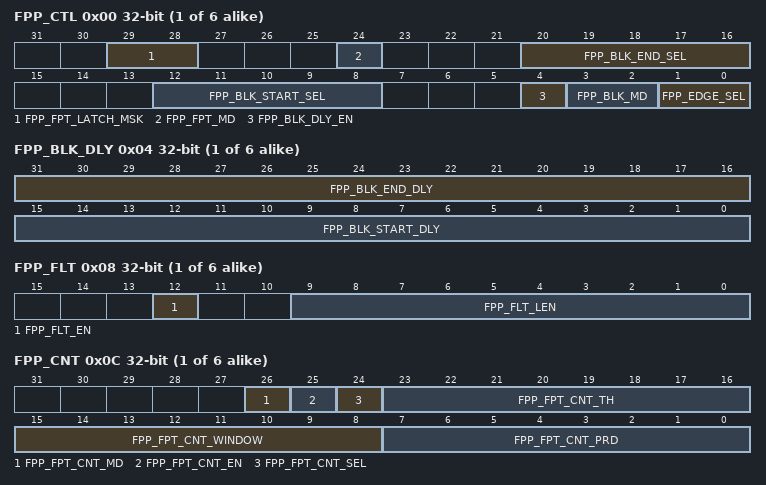
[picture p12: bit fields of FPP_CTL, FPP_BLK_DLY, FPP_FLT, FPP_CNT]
  0x00 FPP_CTL
    [29:28] FPP_FPT_LATCH_MSK — bit28对应屏蔽锁存的异常（fault_latch_out） bit29对应屏蔽计数产生的异常 0：不屏蔽； 1：屏蔽。
    [24] FPP_FPT_MD — 异常预处理异常模式配置。 0：正常模式； 1：一个blanking周期产生一次异常。
    [20:16] FPP_BLK_END_SEL — 异常预处理 blanking time end信号选择。从所有事件集合中选择。
    [12:8] FPP_BLK_START_SEL — 异常预处理 blanking time start信号选择。从所有事件集合中选择。
    [4] FPP_BLK_DLY_EN — 异常预处理blanking信号是否延迟使能。 0：不使能； 1：使能。
    [3:2] FPP_BLK_MD — 异常预处理 blanking time模式配置。 00: 没有blanking； 01：正常blanking； 10：延迟blanking； 11：预留。
    [1:0] FPP_EDGE_SEL — 异常预处理0~5 异常信号沿选择。 00：输入异常信号直接使用； 10：输入异常信号取反使用； 10：输入异常信号取上升沿； 11：输入异常信号取下降沿。
  0x04 FPP_BLK_DLY
    [31:16] FPP_BLK_END_DLY — 异常预处理blanking time end信号延迟配置。
    [15:0] FPP_BLK_START_DLY — 异常预处理blanking time start信号延迟配置。
  0x08 FPP_FLT
    [12] FPP_FLT_EN — 异常预处理信号信号滤波使能配置。 0：不滤波； 1：滤波。
    [9:0] FPP_FLT_LEN — 异常预处理信号信号滤波长度配置。
  0x0C FPP_CNT
    [26] FPP_FPT_CNT_MD — Fault计数模式配置： 'b0：计数时间窗内fault出现的PWM周期个数，统计计数时间窗内出现过fault信号的PWM周期个数； 'b1：计数时间窗内fault持续有效的PWM周期个数，当fault信号失效（为电平），fault计数器即清零。
    [25] FPP_FPT_CNT_EN — 异常预处理异常计数使能。 0：不使能； 1：使能。
    [24] FPP_FPT_CNT_SEL — 异常预处理 用于异常计数的异常信号选择。 0：选择滤波前的异常； 1：选择滤波后的异常。
    [23:16] FPP_FPT_CNT_TH — 异常计数门限
    [15:8] FPP_FPT_CNT_WINDOW — 异常计数窗口长度，以PWM计数周期为单位，在窗口时段对异常计数，当异常持续有效时，每个PWM周期计数一次。
    [7:0] FPP_FPT_CNT_PRD — 异常计数周期，以PWM计数周期为单位。
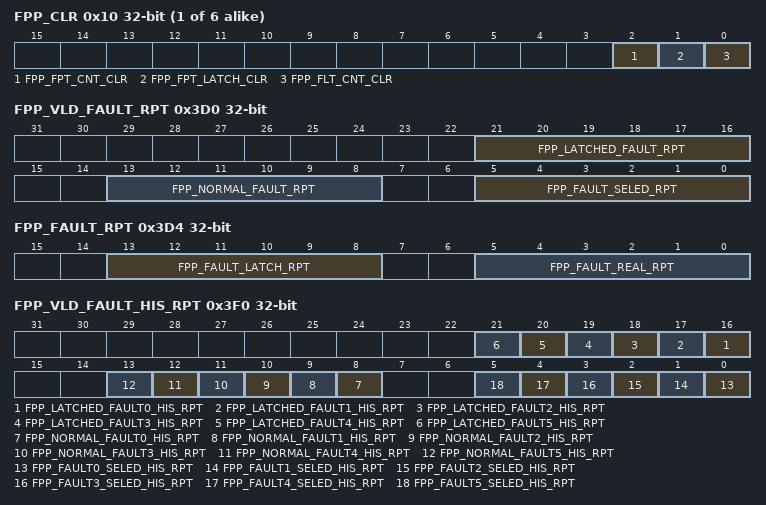
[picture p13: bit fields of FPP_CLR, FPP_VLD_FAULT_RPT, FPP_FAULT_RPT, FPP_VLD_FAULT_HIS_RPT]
  0x10 FPP_CLR
    [2] FPP_FPT_CNT_CLR — 异常预处理0~5 异常计数计数器清零，写1产生脉冲。
    [1] FPP_FPT_LATCH_CLR — 异常预处理0~5 锁存的异常信号清除，写1产生脉冲。
    [0] FPP_FLT_CNT_CLR — 异常预处理0~5 滤波计数清零配置。写1产生脉冲。
  0x14 FPP_FAULT_IN_MSEL
    [20:0] FPP_FAULT_IN_MSEL — 当前Fault处理单元输入Fault信号选择，mask_or选择方式，比特位置1表示选择对应信号，选中的信号做或运算后产生一个Fault输入信号，各比特位对应选择的Fault信号如下： bit20：eqep_err bit19：input_xbar_fault[3] bit18：input_xbar_fault[2] bit17：input_xbar_fault[1] bit16：input_xbar_fault[0] bit15：pwm_xbar_fault[15] bit14：pwm_xbar_fault[14] ... bit0：pwm_xbar_fault[0]
0x3D0 FPP_VLD_FAULT_RPT ro
  [21:16] FPP_LATCHED_FAULT_RPT — 经过和有效区间相与后的锁存异常信号上报；只读。
  [13:8] FPP_NORMAL_FAULT_RPT — 经过和有效区间相与后的普通异常信号上报；只读。
  [5:0] FPP_FAULT_SELED_RPT — 通过cfg_fpp_edge_sel选择后的fault信号上报；只读。
0x3D4 FPP_FAULT_RPT ro
  [13:8] FPP_FAULT_LATCH_RPT — 输出给前保护模块和后保护模块的锁存异常信号；只读
  [5:0] FPP_FAULT_REAL_RPT — 输出给前保护模块和后保护模块的实时异常信号；只读。
{0x3D8+4i} FPP_FAULT_CNT_RPT[{i}] (i=0..5) ro — FPP_FAULT_CNT_RPT%S
  [7:0] FPP_FAULT_CNT_RPT — 异常计数上报；只读。
0x3F0 FPP_VLD_FAULT_HIS_RPT
  [n+16] FPP_LATCHED_FAULT{n}_HIS_RPT (n=0..5) — 经过和有效区间相与后的锁存异常信号{n}上报；上报历史状态，软件写1清零。
  [n+8] FPP_NORMAL_FAULT{n}_HIS_RPT (n=0..5) — 经过和有效区间相与后的普通异常信号{n}上报；上报历史状态，软件写1清零。
  [n] FPP_FAULT{n}_SELED_HIS_RPT (n=0..5) — 通过cfg_fpp_edge_sel选择后的fault{n}信号上报；上报历史状态，软件写1清零。
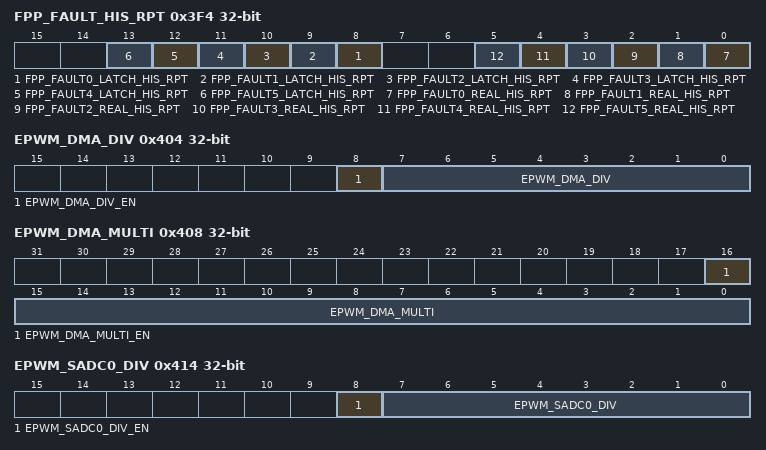
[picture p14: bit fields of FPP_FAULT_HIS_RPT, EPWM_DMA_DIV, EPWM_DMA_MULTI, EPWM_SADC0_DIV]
0x3F4 FPP_FAULT_HIS_RPT
  [n+8] FPP_FAULT{n}_LATCH_HIS_RPT (n=0..5) — 输出给前保护模块和后保护模块的锁存异常信号{n}；上报历史状态，软件写1清零。
  [n] FPP_FAULT{n}_REAL_HIS_RPT (n=0..5) — 输出给前保护模块和后保护模块的实时异常信号{n}；上报历史状态，软件写1清零。
0x3F8 EPWM_FAST_MASK
  [0] FPP_FAST_MASK — 快速保护fault模式屏蔽： 'b0：不屏蔽 'b1：屏蔽 当前寄存器各比特位均为准静态配置寄存器，建议在pwm_en=0时改变配置值。
0x400 EPWM_DMA_MSEL
  [23:0] EPWM_DMA_MSEL — 用于产生DMA请求信号的同步信号选择。Mask_OR的选择方式。 0：不选择该同步信号。 1：选择该同步信号。 从输出事件可选同步集合中选择，bit[23:0]分别对应：
0x404 EPWM_DMA_DIV
  [8] EPWM_DMA_DIV_EN — 对选择后的DMA请求信号的分频使能 0：不分频； 1：支持分频。
  [7:0] EPWM_DMA_DIV — 选择后的DMA请求信号分频配置。
0x408 EPWM_DMA_MULTI
  [16] EPWM_DMA_MULTI_EN — 对DMA请求信号分频后的信号进行倍频使能配置， 0：不使能倍频； 1：使能倍频。
  [15:0] EPWM_DMA_MULTI — 对DMA请求信号分频后信号的倍频配置。
0x410 EPWM_SADC0_MSEL
  [23:0] EPWM_SADC0_MSEL — 用于产生SARADC0请求信号的同步信号选择。Mask_OR的选择方式。 0：不选择该同步信号。 1：选择该同步信号。 bit[23:0]分别对应：
0x414 EPWM_SADC0_DIV
  [8] EPWM_SADC0_DIV_EN — 对选择后的SARADC0请求信号的分频使能 0：不分频； 1：支持分频。
  [7:0] EPWM_SADC0_DIV — 选择后的SARADC0请求信号分频配置。
0x418 EPWM_SADC0_MULTI
  [16] EPWM_SADC0_MULTI_EN — 对SARADC0请求信号分频后的信号进行倍频使能配置， 0：不使能倍频； 1：使能倍频。
  [15:0] EPWM_SADC0_MULTI — 对SARADC0请求信号分频后信号的倍频配置。
0x420 EPWM_SADC1_MSEL
  [23:0] EPWM_SADC1_MSEL — 用于产生SARADC1请求信号的同步信号选择。Mask_OR的选择方式。 0：不选择该同步信号。 1：选择该同步信号。 bit[23:0]分别对应：
0x424 EPWM_SADC1_DIV
  [8] EPWM_SADC1_DIV_EN — 对选择后的SARADC1请求信号的分频使能 0：不分频； 1：支持分频。
  [7:0] EPWM_SADC1_DIV — 选择后的SARADC1请求信号分频配置。
0x428 EPWM_SADC1_MULTI
  [16] EPWM_SADC1_MULTI_EN — 对SARADC1请求信号分频后的信号进行倍频使能配置， 0：不使能倍频； 1：使能倍频。
  [15:0] EPWM_SADC1_MULTI — 对SARADC1请求信号分频后信号的倍频配置。
0x430 EPWM_EVTINT_MSEL
  [23:0] EPWM_EVTINT_MSEL — 用于产生事件中断请求信号的同步信号选择。Mask_OR的选择方式。 0：不选择该同步信号。 1：选择该同步信号。 bit[23:0]分别对应：
0x434 EPWM_EVTINT_DIV
  [8] EPWM_EVTINT_DIV_EN — 对选择后的事件中断请求信号的分频使能 0：不分频； 1：支持分频。
  [7:0] EPWM_EVTINT_DIV — 选择后的事件中断请求信号分频配置。
0x438 EPWM_EVTINT_MULTI
  [16] EPWM_EVTINT_MULTI_EN — 对事件中断请求信号分频后的信号进行倍频使能配置， 0：不使能倍频； 1：使能倍频。
  [15:0] EPWM_EVTINT_MULTI — 对事件中断请求信号分频后信号的倍频配置。
0x43C EPWM_SYNCOUT
  [27:24] EPWM_SYNCOUT1_DLY — 同步信号输出1选择后的延迟配置。
  [19:16] EPWM_SYNCOUT0_DLY — 同步信号输出0选择后的延迟配置。
  [12:8] EPWM_SYNCOUT1_SEL — 同步信号输出1选择配置；采用sel模式。
  [4:0] EPWM_SYNCOUT0_SEL — 同步信号输出0选择配置；采用sel模式。
0x450 CMPC_BDAC_TRG
  [20:16] BDAC_SYNC_SEL — 从输出事件可选同步集合中选择一个事件作为BDAC控制模块的同步信号： 'd0：zero_evt; ...... d'23：timer_1sync; others：无触发信号
  [12:8] CMPC_BLK_SEL — 从输出事件可选同步集合中选择一个事件作为模拟比较器控制模块的消隐触发信号： 'd0：zero_evt; ...... d'23：timer_1sync; others：无触发信号
  [4:0] CMPC_SYNC_SEL — 从输出事件可选同步集合中选择一个事件作为模拟比较器控制模块的同步信号： 'd0：zero_evt; ...... d'23：timer_1sync; others：无触发信号 当前寄存器各比特位均为准静态配置寄存器，建议在pwm_en=0时改变配置值。
0x480 EPWM_INT_EN
  [15:0] EPWM_INT_EN — epwm中断使能配置。 0: 不使能中断； 1: 使能中断。 bit[13:0] 对应 bit[15:14] 预留。
0x484 EPWM_INT_MASK
  [15:0] EPWM_INT_MASK — epwm中断屏蔽寄存器配置。 0: 不屏蔽中断； 1：屏蔽中断。 bit[13:0] 对应 bit[15:14] 预留。
0x488 EPWM_INT_FORCE_IND
  [15:0] EPWM_INT_FORCE_IND — epwm软件强制产生中断配置 0：不产生中断； 1：软件强制产生相应的测试中断，硬件自清零 bit[15:14] 预留。
0x48C EPWM_INT_CLR
  [15:0] EPWM_INT_CLR — epwm中断清除配置。 写1表示清除相应的中断状态，硬件自清零 bit[15:14] 预留。
0x490 EPWM_INT_RAW_RPT ro
  [15:0] EPWM_INT_RAW_RPT — EPWM中断MASK前RAW 中断状态上报 bit[15:14] 预留。
0x494 EPWM_INT_STATUS_RPT ro
  [15:0] EPWM_INT_STATUS_RPT — EPWM中断MASK后中断状态上报 bit[15:14] 预留。
0x500 CAP_TBCNT_CTRL
  [24] TCNT_CAPTURE_EN — 使用故障信号锁存时基计数器计数值的使能 'b0：不使能 'b1：使能
  [23:20] CAP_TCNT_SHD_SEL — 在影子上报模式下，将锁存计数值复制到影子寄存器的触发事件： 'd0：过零事件 'd1：周期事件 'd2：过零事件和周期事件的或事件 'd3：scmp_evt_up[0] 'd4：scmp_evt_up[1] 'd5：scmp_evt_up[2] 'd6：scmp_evt_up[3] 'd7：scmp_evt_down[0] 'd8：scmp_evt_down[1] 'd9：scmp_evt_down[2] 'd10：scmp_evt_down[3] others：无效选择
  [16] CAP_TCNT_RPT_MD — 上报故障锁存TB计数值的模式： 'b0：影子上报模式，故障信号触发的锁存计数值在影子触发信号到来后复制到影子寄存器，软件读取锁存值时读到的是影子寄存器的值； 'b1：立即上报模式，软件读取锁存值时读到的是故障信号触发的锁存计数值
  [13:12] CAP_TCNT_CLR_SEL — 所选故障信号完成一次TB计数值锁存后，自动进入锁存保护状态，将不再响应后继所选故障信号的锁存动作，直至选择下列触发事件之一清除锁存保护后，再进行下一次锁存： 'b00：选择过零事件（zero_evt） 'b01：选择周期事件（prd_evt） 'b10：选择过零事件和周期事件的或事件 'b11：选择故障锁存保护的软件清除事件
  [11:0] CAP_TCNT_MSEL — 以Mask_OR方式从6个fault_real信号和6个fault_latch信号的上升沿中选择一个或多个（做或运算），作为锁存TB 计数值的锁存信号； ，cfg_cap_tbcnt_msel最低比特对应选择fault_real_pos[0]，最高比特对应选择fault_latch_pos[5]。 当前寄存器各比特位均为准静态配置寄存器，建议在pwm_en=0时改变配置值。
0x504 CAP_PRT_CLR
  [0] CAP_LOCKED_CLR — 故障锁存保护的软件清除事件，故障信号完成一次TB计数值锁存后，自动进入锁存保护状态，将不再响应后继所选故障信号的锁存动作，当前寄存器写1产生脉冲，可选择作为清除锁存保护的触发事件。 动态配置寄存器
0x508 CAP_TBCNT_RPT ro
  [24] CAP_TCNT_DIR_RPT — 故障锁存的计数方向上报，上报影子值或直接锁存值，视寄存器CFG_CAP_TBCNT_CTRL[cfg_cap_tcnt_rpt_md]的配置值而定 'b0：向下计数 'b1：向上计数
  [21:0] CAP_TCNT_RPT — 故障锁存的计数值上报，上报影子值或直接锁存值，视寄存器CFG_CAP_TBCNT_CTRL[cfg_cap_tcnt_rpt_md]的配置值而定
0x50C CAP_TBCNT_FLG_RPT
  [0] CAP_TCNT_FLG_RPT — 故障锁存的TB计数值的状态上报，置1表明发生了TB计数值锁存。软件写1清。
0x510 VALLEY_SW_CTRL
  [27:24] VALLEY_OUT_EN — 4比特中最低比特位对应fault通道0的fault上升沿输出，最高比特位对应fault通道3的fault上升沿输出；4比特中相应比特位置1，则以延迟后的谐振脉冲替代该fault通道的fault上升沿输出，否则输出fault上升沿信号。经过此步骤处理后的信号成为时基计数器的时基同步信号源之一。
  [20] RSNTPL_DLY_EN — 谐振指示脉冲的延迟使能 'b0：谐振脉冲不做延迟； 'b1：谐振脉冲做延迟。
  [18:16] VSW_TARGET_EDGE — 选择以第几个沿作为谐振指示脉冲： 'd0：不选沿； 'd1：选第1个沿； ...... 'd7：选第7个沿。
  [13:12] VSW_EDGE_MODE — 沿模式选择： 'd0：上升沿； 'd1：下降沿； 'd2,'d3：双沿
  [11:8] VSW_TRGSEL — 选择谷值检测和捕获的触发信号： 'd0：谷值开关软件触发事件 'd1：过零事件（zero_evt） 'd2：周期事件（prd_evt） d'3：过零事件和周期事件的或 d'4：SCMPC向上计数比较事件（scmpc_up_evt） d'5：SCMPC向下计数比较事件（scmpc_dw_evt） d'6：SCMPD向上计数比较事件（scmpd_up_evt） d'7：SCMPD向下计数比较事件（scmpd_dw_evt） d'8：选择fault通道0的实时fault信号 'd9：选择fault通道1的实时fault信号 'd10：选择fault通道2的实时fault信号 'd11：选择fault通道3的实时fault信号 others：无触发（谷值开关功能无法正常工作）
  [5:4] VSW_SRCSEL — 谷值开关功能检测的fault信号来源选择： 'd0：选择fault通道0的实时fault信号（fault_real_out） 'd1：选择fault通道1的实时fault信号 'd2：选择fault通道2的实时fault信号 'd3：选择fault通道3的实时fault信号
  [0] VSW_EN — 谷值开关功能的使能配置，置1谷值开关功能生效。 当前寄存器地址中，各比特位均为准静态配置寄存器，其中cfg_vsw_en建议在pwm_en=0时改变配置值，其余比特位建议在cfg_vsw_en=0时改变配置值。
0x514 VALLEY_SFT_TRG
  [0] VSW_SFT_TRG — 谷值开关软件触发事件，写1产生脉冲。 动态配置寄存器
0x518 EDGE_NUM_RPT ro
  [2:0] EDGE_DET_NUM_RPT — 实时上报当前已检测到的跳变沿计数值，当检测到数量与寄存器CFG_VALLEY_SW_CTRL[cfg_vsw_target_edge]的配置相等，跳变沿计数值将被置0，同时将产生谐振指示脉冲。将寄存器CFG_VALLEY_SW_CTRL[cfg_vsw_target_edge]置0，将使得跳变沿计数值被清零（此时不会产生谐振指示脉冲）。
0x51C VALLEY_CAP
  [7:4] VSWCNT_STOP — 选择从第几个跳变沿结束（触发信号到来后开始计算）跳变沿间隔计数，此处跳变沿包括上升沿和下降沿： 'd0：不开始 'd1：第1个跳变沿 'd2：第2个跳变沿 ...... 'd15：第15个跳变沿
  [3:0] VSWCNT_START — 选择从第几个跳变沿开始（触发信号到来后开始计算）进行跳变沿间隔计数，此处跳变沿包括上升沿和下降沿： 'd0：不开始 'd1：第1个跳变沿 'd2：第2个跳变沿 ...... 'd15：第15个跳变沿 当前寄存器各比特位均为准静态配置寄存器，建议在cfg_vsw_en=0时改变配置值。。
0x520 VSW_DLY_CAL
  [26:24] VSW_DLY_CAL_SEL — 谐振指示脉冲延迟处理所需延迟值计算方式选择： 'd0：直接采用软件配置延迟值 'd1：跳变沿间隔计数值+软件配置值 'd2：跳变沿间隔计数值/2+软件配置值 'd3：跳变沿间隔计数值/4+软件配置值 'd4：跳变沿间隔计数值/8+软件配置值 'd5~d7：跳变沿间隔计数值/16+软件配置值
  [21:0] VSW_SFT_DLY — 软件配置延迟值，可用于谐振指示脉冲延迟值计算 当前寄存器各比特位均为准静态配置寄存器，建议在cfg_vsw_en=0时改变配置值。。
0x524 CAP_START_END_RPT ro
  [1] VSWCNT_STOP_RPT — 当CFG_VALLEY_SW_CTRL[cfg_vsw_trgsel]选择的触发信号到来后，检测到CFG_VALLEY_CAP[cfg_vswcnt_stop]配置的结束跳变沿，当前上报值拉高，直至下一次触发信号到来后，当前上报值再拉低。
  [0] VSWCNT_START_RPT — 当CFG_VALLEY_SW_CTRL[cfg_vsw_trgsel]选择的触发信号到来后，检测到CFG_VALLEY_CAP[cfg_vswcnt_start]配置的起始跳变沿，当前上报值拉高，直至下一次触发信号到来后，当前上报值再拉低。
0x528 VSWCNT_RPT ro
  [21:0] VSWCNT_VAL_RPT — 当脉冲间隔计数停止脉冲出现时，锁存上报脉冲间隔计数值（vswcnt）。
0x52C RESP_DLY_RPT ro
  [21:0] RES_PULSE_DLY_RPT — 基于寄存器CFG_VSW_DLY_CAL配置计算得到的谐振指示脉冲延迟值上报。
0x530 TRIP_OUT_MSEL
  [17:0] TRIP_OUT_MSEL — 以MASK_OR方式选择以下保护动作指示（高电平时表示产生该类型动作）和FAULT信号输出至XBAR bit0：a支路CBC动作指示，电平信号，高电平表示当前CBC保护条件满足 bit1：a支路OS动作指示，电平信号，高电平表示当前OS保护条件满足 bit2：a支路无约束动作指示，电平信号，高电平表示当前无约束保护条件满足 bit3：b支路CBC动作指示，电平信号，高电平表示当前CBC保护条件满足 bit4：b支路OS动作指示，电平信号，高电平表示当前OS保护条件满足 bit5：b支路无约束动作指示，电平信号，高电平表示当前无约束保护条件满足 bit6：FPP_FAULT_REAL[0] bit7：FPP_FAULT_REAL[1] ... bit11：FPP_FAULT_REAL[5] bit12：FPP_FAULT_LATCH [0] bit13：FPP_FAULT_LATCH [1] ... bit17：FPP_FAULT_LATCH [5] 需注意，当CBC、OS、和无约束动作的条件同时满足时，真正生效的动作是按照高阻、置0、置1、取反的从高到低优先级出现的。上述电平信号仅代表CBC、OS、无约束动作的条件满足。
0x600 EPWM_TEST_SEL
  [8n+4:8n] EPWM_TEST{n}_SEL (n=0..3) — TEST{n} 信号选择
0xFFC EPWM_TAIL reset 0x4D774D77
  [31:16] TAIL_SW_RO ro — 软件只读硬件上报寄存器
  [15:0] TAIL_SW_WR — 软件测试读写寄存器，硬件无访问
